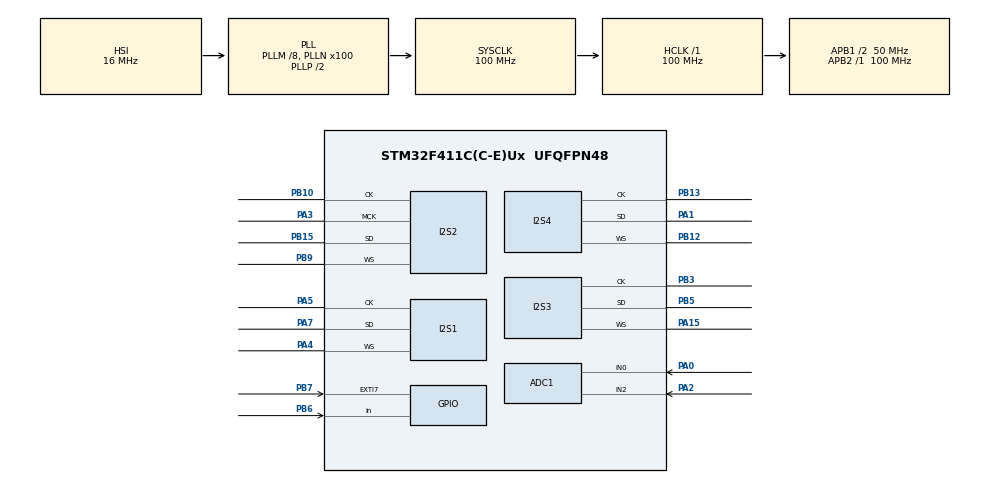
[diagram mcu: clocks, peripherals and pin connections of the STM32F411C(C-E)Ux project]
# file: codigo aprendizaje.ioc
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ADC1.Channel-1\#ChannelRegularConversion=ADC_CHANNEL_0
ADC1.Channel-5\#ChannelRegularConversion=ADC_CHANNEL_2
ADC1.ClockPrescaler=ADC_CLOCK_SYNC_PCLK_DIV4
ADC1.ContinuousConvMode=ENABLE
ADC1.DMAContinuousRequests=ENABLE
ADC1.InjNumberOfConversion=0
ADC1.NbrOfConversion=2
ADC1.NbrOfConversionFlag=1
ADC1.Rank-1\#ChannelRegularConversion=1
ADC1.Rank-5\#ChannelRegularConversion=2
ADC1.SamplingTime-1\#ChannelRegularConversion=ADC_SAMPLETIME_3CYCLES
ADC1.SamplingTime-5\#ChannelRegularConversion=ADC_SAMPLETIME_3CYCLES
ADC1.master=1
Dma.ADC1.0.Direction=DMA_PERIPH_TO_MEMORY
Dma.ADC1.0.FIFOMode=DMA_FIFOMODE_DISABLE
Dma.ADC1.0.Instance=DMA2_Stream0
Dma.ADC1.0.MemDataAlignment=DMA_MDATAALIGN_WORD
Dma.ADC1.0.MemInc=DMA_MINC_ENABLE
Dma.ADC1.0.Mode=DMA_CIRCULAR
Dma.ADC1.0.PeriphDataAlignment=DMA_PDATAALIGN_WORD
Dma.ADC1.0.PeriphInc=DMA_PINC_DISABLE
Dma.ADC1.0.Priority=DMA_PRIORITY_MEDIUM
Dma.Request0=ADC1
I2S1.AudioFreq=I2S_AUDIOFREQ_96K
I2S1.DataFormat=I2S_DATAFORMAT_24B
I2S1.ErrorAudioFreq=-2.34 %
I2S1.FullDuplexMode=I2S_FULLDUPLEXMODE_DISABLE
I2S1.Instance=SPI$Index
I2S1.RealAudioFreq=93.75 KHz
I2S1.VirtualMode=I2S_MODE_MASTER
I2S2.AudioFreq=I2S_AUDIOFREQ_96K
I2S2.DataFormat=I2S_DATAFORMAT_24B
I2S2.ErrorAudioFreq=-2.34 %
I2S2.FullDuplexMode=I2S_FULLDUPLEXMODE_DISABLE
I2S2.Instance=SPI$Index
I2S2.RealAudioFreq=93.75 KHz
I2S2.VirtualMode=I2S_MODE_MASTER
I2S3.AudioFreq=I2S_AUDIOFREQ_96K
I2S3.DataFormat=I2S_DATAFORMAT_24B
I2S3.ErrorAudioFreq=-2.34 %
I2S3.FullDuplexMode=I2S_FULLDUPLEXMODE_DISABLE
I2S3.Instance=SPI$Index
I2S3.RealAudioFreq=93.75 KHz
I2S3.VirtualMode=I2S_MODE_MASTER
I2S4.ErrorAudioFreq=0.0 %
I2S4.FullDuplexMode=I2S_FULLDUPLEXMODE_DISABLE
I2S4.Instance=SPI$Index
I2S4.RealAudioFreq=8.0 KHz
I2S4.VirtualMode=I2S_MODE_MASTER
Mcu.Family=STM32F4
Mcu.Name=STM32F411C(C-E)Ux
Mcu.Package=UFQFPN48
NVIC.DMA2_Stream0_IRQn=true\:0\:0\:false\:false\:true\:false\:true\:true
NVIC.EXTI9_5_IRQn=true\:0\:0\:false\:false\:true\:true\:true\:true
NVIC.PriorityGroup=NVIC_PRIORITYGROUP_4
PA0-WKUP.Signal=ADCx_IN0
PA1.Mode=Half_Duplex_Master
PA1.Signal=I2S4_SD
PA15.Mode=Half_Duplex_Master
PA15.Signal=I2S3_WS
PA2.Signal=ADCx_IN2
PA3.Mode=Master_Clock_Activated
PA3.Signal=I2S2_MCK
PA4.Mode=Half_Duplex_Master
PA4.Signal=I2S1_WS
PA5.Mode=Half_Duplex_Master
PA5.Signal=I2S1_CK
PA7.Mode=Half_Duplex_Master
PA7.Signal=I2S1_SD
PB10.Mode=Half_Duplex_Master
PB10.Signal=I2S2_CK
PB12.Mode=Half_Duplex_Master
PB12.Signal=I2S4_WS
PB13.Mode=Half_Duplex_Master
PB13.Signal=I2S4_CK
PB15.Mode=Half_Duplex_Master
PB15.Signal=I2S2_SD
PB3.Mode=Half_Duplex_Master
PB3.Signal=I2S3_CK
PB5.Mode=Half_Duplex_Master
PB5.Signal=I2S3_SD
PB6.Signal=GPIO_Input
PB7.GPIO_ModeDefaultEXTI=GPIO_MODE_IT_FALLING
PB7.GPIO_PuPd=GPIO_PULLUP
PB7.Signal=GPXTI7
PB9.Mode=Half_Duplex_Master
PB9.Signal=I2S2_WS
ProjectManager.HeapSize=0x200
ProjectManager.StackSize=0x400
ProjectManager.TargetToolchain=STM32CubeIDE
RCC.48MHZClocksFreq_Value=50000000
RCC.AHBFreq_Value=100000000
RCC.APB1CLKDivider=RCC_HCLK_DIV2
RCC.APB1Freq_Value=50000000
RCC.APB1TimFreq_Value=100000000
RCC.APB2Freq_Value=100000000
RCC.APB2TimFreq_Value=100000000
RCC.CortexFreq_Value=100000000
RCC.HCLKFreq_Value=100000000
RCC.HSE_VALUE=25000000
RCC.HSI_VALUE=16000000
RCC.LSE_VALUE=32768
RCC.PLLM=8
RCC.PLLN=100
RCC.RCC_MCO1Source=RCC_MCO1SOURCE_PLLCLK
RCC.SYSCLKFreq_VALUE=100000000
RCC.SYSCLKSource=RCC_SYSCLKSOURCE_PLLCLK
RCC.VCOOutputFreq_Value=200000000
SH.ADCx_IN0.0=ADC1_IN0,IN0
SH.ADCx_IN2.0=ADC1_IN2,IN2
board=custom

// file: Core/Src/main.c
/* USER CODE BEGIN Header */
/**
  ******************************************************************************
  * @file           : main.c
  * @brief          : Main program body
  ******************************************************************************
  * @attention
  *
  * Copyright (c) 2023 STMicroelectronics.
  * All rights reserved.
  *
  * This software is licensed under terms that can be found in the LICENSE file
  * in the root directory of this software component.
  * If no LICENSE file comes with this software, it is provided AS-IS.
  *
  ******************************************************************************
  */
/* USER CODE END Header */
#include "main.h"
#include "math.h"

ADC_HandleTypeDef hadc1;
DMA_HandleTypeDef hdma_adc1;

I2S_HandleTypeDef hi2s1;
I2S_HandleTypeDef hi2s2;
I2S_HandleTypeDef hi2s3;
I2S_HandleTypeDef hi2s4;

/* USER CODE BEGIN PV */
uint32_t AudioIn[2];
uint16_t AudioCh1[2];
uint16_t AudioCh2[2];
uint16_t AudioCh3[2];
uint16_t AudioCh4[2];
/* USER CODE END PV */

void SystemClock_Config(void);
void PeriphCommonClock_Config(void);
static void MX_GPIO_Init(void);
static void MX_DMA_Init(void);
static void MX_ADC1_Init(void);
static void MX_I2S1_Init(void);
static void MX_I2S2_Init(void);
static void MX_I2S3_Init(void);
static void MX_I2S4_Init(void);

int main(void)
{

  /* MCU Configuration--------------------------------------------------------*/

  /* Reset of all peripherals, Initializes the Flash interface and the Systick. */
  HAL_Init();

  /* Configure the system clock */
  SystemClock_Config();

/* Configure the peripherals common clocks */
  PeriphCommonClock_Config();

  /* Initialize all configured peripherals */
  MX_GPIO_Init();
  MX_DMA_Init();
  MX_ADC1_Init();
  MX_I2S1_Init();
  MX_I2S2_Init();
  MX_I2S3_Init();
  MX_I2S4_Init();
  /* USER CODE BEGIN 2 */
  HAL_ADC_Start_DMA(&hadc1, AudioIn, 2);

  /* USER CODE END 2 */

  /* Infinite loop */
  while (1)
  {
	  HAL_I2S_Transmit_DMA(&hi2s1, AudioCh1, 1);
	  HAL_I2S_Transmit_DMA(&hi2s2, AudioCh2, 1);
	  HAL_I2S_Transmit_DMA(&hi2s3, AudioCh3, 1);
	  HAL_I2S_Transmit_DMA(&hi2s4, AudioCh4, 1);
  }
}

void SystemClock_Config(void)
{
  RCC_OscInitTypeDef RCC_OscInitStruct = {0};
  RCC_ClkInitTypeDef RCC_ClkInitStruct = {0};

  /** Configure the main internal regulator output voltage
  */
  __HAL_RCC_PWR_CLK_ENABLE();
  __HAL_PWR_VOLTAGESCALING_CONFIG(PWR_REGULATOR_VOLTAGE_SCALE1);

  /** Initializes the RCC Oscillators according to the specified parameters
  * in the RCC_OscInitTypeDef structure.
  */
  RCC_OscInitStruct.OscillatorType = RCC_OSCILLATORTYPE_HSI;
  RCC_OscInitStruct.HSIState = RCC_HSI_ON;
  RCC_OscInitStruct.HSICalibrationValue = RCC_HSICALIBRATION_DEFAULT;
  RCC_OscInitStruct.PLL.PLLState = RCC_PLL_ON;
  RCC_OscInitStruct.PLL.PLLSource = RCC_PLLSOURCE_HSI;
  RCC_OscInitStruct.PLL.PLLM = 8;
  RCC_OscInitStruct.PLL.PLLN = 100;
  RCC_OscInitStruct.PLL.PLLP = RCC_PLLP_DIV2;
  RCC_OscInitStruct.PLL.PLLQ = 4;
  if (HAL_RCC_OscConfig(&RCC_OscInitStruct) != HAL_OK)
  {
    Error_Handler();
  }

  /** Initializes the CPU, AHB and APB buses clocks
  */
  RCC_ClkInitStruct.ClockType = RCC_CLOCKTYPE_HCLK|RCC_CLOCKTYPE_SYSCLK
                              |RCC_CLOCKTYPE_PCLK1|RCC_CLOCKTYPE_PCLK2;
  RCC_ClkInitStruct.SYSCLKSource = RCC_SYSCLKSOURCE_PLLCLK;
  RCC_ClkInitStruct.AHBCLKDivider = RCC_SYSCLK_DIV1;
  RCC_ClkInitStruct.APB1CLKDivider = RCC_HCLK_DIV2;
  RCC_ClkInitStruct.APB2CLKDivider = RCC_HCLK_DIV1;

  if (HAL_RCC_ClockConfig(&RCC_ClkInitStruct, FLASH_LATENCY_3) != HAL_OK)
  {
    Error_Handler();
  }
}

void PeriphCommonClock_Config(void)
{
  RCC_PeriphCLKInitTypeDef PeriphClkInitStruct = {0};

  /** Initializes the peripherals clock
  */
  PeriphClkInitStruct.PeriphClockSelection = RCC_PERIPHCLK_I2S;
  PeriphClkInitStruct.PLLI2S.PLLI2SN = 192;
  PeriphClkInitStruct.PLLI2S.PLLI2SM = 16;
  PeriphClkInitStruct.PLLI2S.PLLI2SR = 2;
  if (HAL_RCCEx_PeriphCLKConfig(&PeriphClkInitStruct) != HAL_OK)
  {
    Error_Handler();
  }
}

static void MX_ADC1_Init(void)
{

  ADC_ChannelConfTypeDef sConfig = {0};

  /** Configure the global features of the ADC (Clock, Resolution, Data Alignment and number of conversion)
  */
  hadc1.Instance = ADC1;
  hadc1.Init.ClockPrescaler = ADC_CLOCK_SYNC_PCLK_DIV4;
  hadc1.Init.Resolution = ADC_RESOLUTION_12B;
  hadc1.Init.ScanConvMode = ENABLE;
  hadc1.Init.ContinuousConvMode = ENABLE;
  hadc1.Init.DiscontinuousConvMode = DISABLE;
  hadc1.Init.ExternalTrigConvEdge = ADC_EXTERNALTRIGCONVEDGE_NONE;
  hadc1.Init.ExternalTrigConv = ADC_SOFTWARE_START;
  hadc1.Init.DataAlign = ADC_DATAALIGN_RIGHT;
  hadc1.Init.NbrOfConversion = 2;
  hadc1.Init.DMAContinuousRequests = ENABLE;
  hadc1.Init.EOCSelection = ADC_EOC_SINGLE_CONV;
  if (HAL_ADC_Init(&hadc1) != HAL_OK)
  {
    Error_Handler();
  }

  /** Configure for the selected ADC regular channel its corresponding rank in the sequencer and its sample time.
  */
  sConfig.Channel = ADC_CHANNEL_0;
  sConfig.Rank = 1;
  sConfig.SamplingTime = ADC_SAMPLETIME_3CYCLES;
  if (HAL_ADC_ConfigChannel(&hadc1, &sConfig) != HAL_OK)
  {
    Error_Handler();
  }

  /** Configure for the selected ADC regular channel its corresponding rank in the sequencer and its sample time.
  */
  sConfig.Channel = ADC_CHANNEL_2;
  sConfig.Rank = 2;
  if (HAL_ADC_ConfigChannel(&hadc1, &sConfig) != HAL_OK)
  {
    Error_Handler();
  }

}

static void MX_I2S1_Init(void)
{

  hi2s1.Instance = SPI1;
  hi2s1.Init.Mode = I2S_MODE_MASTER_TX;
  hi2s1.Init.Standard = I2S_STANDARD_PHILIPS;
  hi2s1.Init.DataFormat = I2S_DATAFORMAT_24B;
  hi2s1.Init.MCLKOutput = I2S_MCLKOUTPUT_DISABLE;
  hi2s1.Init.AudioFreq = I2S_AUDIOFREQ_96K;
  hi2s1.Init.CPOL = I2S_CPOL_LOW;
  hi2s1.Init.ClockSource = I2S_CLOCK_PLL;
  hi2s1.Init.FullDuplexMode = I2S_FULLDUPLEXMODE_DISABLE;
  if (HAL_I2S_Init(&hi2s1) != HAL_OK)
  {
    Error_Handler();
  }

}

static void MX_I2S2_Init(void)
{

  hi2s2.Instance = SPI2;
  hi2s2.Init.Mode = I2S_MODE_MASTER_TX;
  hi2s2.Init.Standard = I2S_STANDARD_PHILIPS;
  hi2s2.Init.DataFormat = I2S_DATAFORMAT_24B;
  hi2s2.Init.MCLKOutput = I2S_MCLKOUTPUT_ENABLE;
  hi2s2.Init.AudioFreq = I2S_AUDIOFREQ_96K;
  hi2s2.Init.CPOL = I2S_CPOL_LOW;
  hi2s2.Init.ClockSource = I2S_CLOCK_PLL;
  hi2s2.Init.FullDuplexMode = I2S_FULLDUPLEXMODE_DISABLE;
  if (HAL_I2S_Init(&hi2s2) != HAL_OK)
  {
    Error_Handler();
  }

}

static void MX_I2S3_Init(void)
{

  hi2s3.Instance = SPI3;
  hi2s3.Init.Mode = I2S_MODE_MASTER_TX;
  hi2s3.Init.Standard = I2S_STANDARD_PHILIPS;
  hi2s3.Init.DataFormat = I2S_DATAFORMAT_24B;
  hi2s3.Init.MCLKOutput = I2S_MCLKOUTPUT_DISABLE;
  hi2s3.Init.AudioFreq = I2S_AUDIOFREQ_96K;
  hi2s3.Init.CPOL = I2S_CPOL_LOW;
  hi2s3.Init.ClockSource = I2S_CLOCK_PLL;
  hi2s3.Init.FullDuplexMode = I2S_FULLDUPLEXMODE_DISABLE;
  if (HAL_I2S_Init(&hi2s3) != HAL_OK)
  {
    Error_Handler();
  }

}

static void MX_I2S4_Init(void)
{

  hi2s4.Instance = SPI4;
  hi2s4.Init.Mode = I2S_MODE_MASTER_TX;
  hi2s4.Init.Standard = I2S_STANDARD_PHILIPS;
  hi2s4.Init.DataFormat = I2S_DATAFORMAT_16B;
  hi2s4.Init.MCLKOutput = I2S_MCLKOUTPUT_DISABLE;
  hi2s4.Init.AudioFreq = I2S_AUDIOFREQ_8K;
  hi2s4.Init.CPOL = I2S_CPOL_LOW;
  hi2s4.Init.ClockSource = I2S_CLOCK_PLL;
  hi2s4.Init.FullDuplexMode = I2S_FULLDUPLEXMODE_DISABLE;
  if (HAL_I2S_Init(&hi2s4) != HAL_OK)
  {
    Error_Handler();
  }

}

static void MX_DMA_Init(void)
{

  /* DMA controller clock enable */
  __HAL_RCC_DMA2_CLK_ENABLE();

  /* DMA interrupt init */
  /* DMA2_Stream0_IRQn interrupt configuration */
  HAL_NVIC_SetPriority(DMA2_Stream0_IRQn, 0, 0);
  HAL_NVIC_EnableIRQ(DMA2_Stream0_IRQn);

}

static void MX_GPIO_Init(void)
{
  GPIO_InitTypeDef GPIO_InitStruct = {0};

  /* GPIO Ports Clock Enable */
  __HAL_RCC_GPIOA_CLK_ENABLE();
  __HAL_RCC_GPIOB_CLK_ENABLE();

  /*Configure GPIO pin : PB6 */
  GPIO_InitStruct.Pin = GPIO_PIN_6;
  GPIO_InitStruct.Mode = GPIO_MODE_INPUT;
  GPIO_InitStruct.Pull = GPIO_NOPULL;
  HAL_GPIO_Init(GPIOB, &GPIO_InitStruct);

  /*Configure GPIO pin : PB7 */
  GPIO_InitStruct.Pin = GPIO_PIN_7;
  GPIO_InitStruct.Mode = GPIO_MODE_IT_FALLING;
  GPIO_InitStruct.Pull = GPIO_PULLUP;
  HAL_GPIO_Init(GPIOB, &GPIO_InitStruct);

  /* EXTI interrupt init*/
  HAL_NVIC_SetPriority(EXTI9_5_IRQn, 0, 0);
  HAL_NVIC_EnableIRQ(EXTI9_5_IRQn);

}

void Error_Handler(void)
{
}
